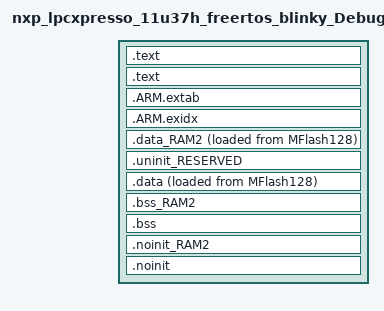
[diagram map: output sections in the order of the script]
/*
 * GENERATED FILE - DO NOT EDIT
 * Copyright (c) 2008-2013 Code Red Technologies Ltd,
 * Copyright 2015, 2018-2019 NXP
 * (c) NXP Semiconductors 2013-2020
 * Generated linker script file for LPC11U37/401
 * Created from linkscript.ldt by FMCreateLinkLibraries
 * Using Freemarker v2.3.23
 * MCUXpresso IDE v11.2.0 [Build 4120] [2020-07-09] on Sep 4, 2020 9:30:54 AM
 */

INCLUDE "nxp_lpcxpresso_11u37h_freertos_blinky_Debug_library.ld"
INCLUDE "nxp_lpcxpresso_11u37h_freertos_blinky_Debug_memory.ld"

ENTRY(ResetISR)

SECTIONS
{
     /* MAIN TEXT SECTION */
    .text : ALIGN(4)
    {
        FILL(0xff)
        __vectors_start__ = ABSOLUTE(.) ;
        KEEP(*(.isr_vector))
        /* Global Section Table */
        . = ALIGN(4) ;
        __section_table_start = .;
        __data_section_table = .;
        LONG(LOADADDR(.data));
        LONG(    ADDR(.data));
        LONG(  SIZEOF(.data));
        LONG(LOADADDR(.data_RAM2));
        LONG(    ADDR(.data_RAM2));
        LONG(  SIZEOF(.data_RAM2));
        __data_section_table_end = .;
        __bss_section_table = .;
        LONG(    ADDR(.bss));
        LONG(  SIZEOF(.bss));
        LONG(    ADDR(.bss_RAM2));
        LONG(  SIZEOF(.bss_RAM2));
        __bss_section_table_end = .;
        __section_table_end = . ;
        /* End of Global Section Table */

        *(.after_vectors*)

    } > MFlash128

    .text : ALIGN(4)
    {
       *(.text*)
       KEEP(*/tasks.o(.rodata*))  /* FreeRTOS Debug Config */
       *(.rodata .rodata.* .constdata .constdata.*)
       . = ALIGN(4);
    } > MFlash128
    /*
     * for exception handling/unwind - some Newlib functions (in common
     * with C++ and STDC++) use this.
     */
    .ARM.extab : ALIGN(4)
    {
        *(.ARM.extab* .gnu.linkonce.armextab.*)
    } > MFlash128

    .ARM.exidx : ALIGN(4)
    {
        __exidx_start = .;
        *(.ARM.exidx* .gnu.linkonce.armexidx.*)
        __exidx_end = .;
    } > MFlash128
 
    _etext = .;
        
    /* DATA section for RamUsb2 */

    .data_RAM2 : ALIGN(4)
    {
        FILL(0xff)
        PROVIDE(__start_data_RAM2 = .) ;
        PROVIDE(__start_data_RamUsb2 = .) ;
        *(.ramfunc.$RAM2)
        *(.ramfunc.$RamUsb2)
        *(.data.$RAM2)
        *(.data.$RamUsb2)
        *(.data.$RAM2.*)
        *(.data.$RamUsb2.*)
        . = ALIGN(4) ;
        PROVIDE(__end_data_RAM2 = .) ;
        PROVIDE(__end_data_RamUsb2 = .) ;
     } > RamUsb2 AT>MFlash128

    /* MAIN DATA SECTION */
    .uninit_RESERVED (NOLOAD) : ALIGN(4)
    {
        _start_uninit_RESERVED = .;
        KEEP(*(.bss.$RESERVED*))
       . = ALIGN(4) ;
        _end_uninit_RESERVED = .;
    } > RamLoc8 AT> RamLoc8

    /* Main DATA section (RamLoc8) */
    .data : ALIGN(4)
    {
       FILL(0xff)
       _data = . ;
       PROVIDE(__start_data_RAM = .) ;
       PROVIDE(__start_data_RamLoc8 = .) ;
       *(vtable)
       *(.ramfunc*)
       KEEP(*(CodeQuickAccess))
       KEEP(*(DataQuickAccess))
       *(RamFunction)
       *(.data*)
       . = ALIGN(4) ;
       _edata = . ;
       PROVIDE(__end_data_RAM = .) ;
       PROVIDE(__end_data_RamLoc8 = .) ;
    } > RamLoc8 AT>MFlash128

    /* BSS section for RamUsb2 */
    .bss_RAM2 : ALIGN(4)
    {
       PROVIDE(__start_bss_RAM2 = .) ;
       PROVIDE(__start_bss_RamUsb2 = .) ;
       *(.bss.$RAM2)
       *(.bss.$RamUsb2)
       *(.bss.$RAM2.*)
       *(.bss.$RamUsb2.*)
       . = ALIGN (. != 0 ? 4 : 1) ; /* avoid empty segment */
       PROVIDE(__end_bss_RAM2 = .) ;
       PROVIDE(__end_bss_RamUsb2 = .) ;
    } > RamUsb2 AT> RamUsb2

    /* MAIN BSS SECTION */
    .bss : ALIGN(4)
    {
        _bss = .;
        PROVIDE(__start_bss_RAM = .) ;
        PROVIDE(__start_bss_RamLoc8 = .) ;
        *(.bss*)
        *(COMMON)
        . = ALIGN(4) ;
        _ebss = .;
        PROVIDE(__end_bss_RAM = .) ;
        PROVIDE(__end_bss_RamLoc8 = .) ;
        PROVIDE(end = .);
    } > RamLoc8 AT> RamLoc8

    /* NOINIT section for RamUsb2 */
    .noinit_RAM2 (NOLOAD) : ALIGN(4)
    {
       PROVIDE(__start_noinit_RAM2 = .) ;
       PROVIDE(__start_noinit_RamUsb2 = .) ;
       *(.noinit.$RAM2)
       *(.noinit.$RamUsb2)
       *(.noinit.$RAM2.*)
       *(.noinit.$RamUsb2.*)
       . = ALIGN(4) ;
       PROVIDE(__end_noinit_RAM2 = .) ;
       PROVIDE(__end_noinit_RamUsb2 = .) ;
    } > RamUsb2 AT> RamUsb2

    /* DEFAULT NOINIT SECTION */
    .noinit (NOLOAD): ALIGN(4)
    {
        _noinit = .;
        PROVIDE(__start_noinit_RAM = .) ;
        PROVIDE(__start_noinit_RamLoc8 = .) ;
        *(.noinit*)
         . = ALIGN(4) ;
        _end_noinit = .;
       PROVIDE(__end_noinit_RAM = .) ;
       PROVIDE(__end_noinit_RamLoc8 = .) ;        
    } > RamLoc8 AT> RamLoc8
    PROVIDE(_pvHeapStart = DEFINED(__user_heap_base) ? __user_heap_base : .);
    PROVIDE(_vStackTop = DEFINED(__user_stack_top) ? __user_stack_top : __top_RamLoc8 - 0);

    /* ## Create checksum value (used in startup) ## */
    PROVIDE(__valid_user_code_checksum = 0 - 
                                         (_vStackTop 
                                         + (ResetISR + 1) 
                                         + (( DEFINED(NMI_Handler) ? NMI_Handler : M0_NMI_Handler ) + 1) 
                                         + (( DEFINED(HardFault_Handler) ? HardFault_Handler : M0_HardFault_Handler ) + 1) 
                                         )
           );

    /* Provide basic symbols giving location and size of main text
     * block, including initial values of RW data sections. Note that
     * these will need extending to give a complete picture with
     * complex images (e.g multiple Flash banks).
     */
    _image_start = LOADADDR(.text);
    _image_end = LOADADDR(.data) + SIZEOF(.data);
    _image_size = _image_end - _image_start;
}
